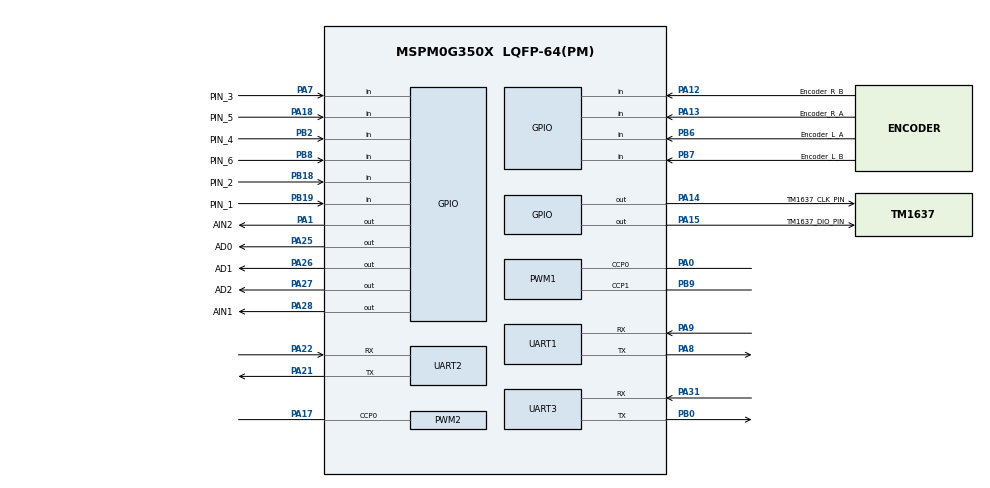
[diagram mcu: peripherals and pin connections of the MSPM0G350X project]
/**
 *
 * @cliArgs --device "MSPM0G350X" --part "Default" --package "LQFP-64(PM)" --product "mspm0_sdk@2.11.00.07"
 * @versions {"tool":"1.28.0+4712"}
 */

/**
 * Import the modules used in this configuration.
 */
const GPIO   = scripting.addModule("/ti/driverlib/GPIO", {}, false);
const GPIO1  = GPIO.addInstance();
const GPIO2  = GPIO.addInstance();
const GPIO3  = GPIO.addInstance();
const GPIO4  = GPIO.addInstance();
const GPIO5  = GPIO.addInstance();
const GPIO6  = GPIO.addInstance();
const GPIO7  = GPIO.addInstance();
const GPIO8  = GPIO.addInstance();
const GPIO9  = GPIO.addInstance();
const GPIO10 = GPIO.addInstance();
const GPIO11 = GPIO.addInstance();
const GPIO12 = GPIO.addInstance();
const GPIO13 = GPIO.addInstance();
const GPIO14 = GPIO.addInstance();
const PWM    = scripting.addModule("/ti/driverlib/PWM", {}, false);
const PWM1   = PWM.addInstance();
const PWM2   = PWM.addInstance();
const SYSCTL = scripting.addModule("/ti/driverlib/SYSCTL");
const TIMER  = scripting.addModule("/ti/driverlib/TIMER", {}, false);
const TIMER1 = TIMER.addInstance();
const UART   = scripting.addModule("/ti/driverlib/UART", {}, false);
const UART1  = UART.addInstance();
const UART2  = UART.addInstance();
const UART3  = UART.addInstance();

/**
 * Write custom configuration values to the imported modules.
 */
GPIO1.$name                          = "GPIO_MOTOR";
GPIO1.associatedPins.create(4);
GPIO1.associatedPins[0].$name        = "AIN1";
GPIO1.associatedPins[0].assignedPort = "PORTA";
GPIO1.associatedPins[0].assignedPin  = "28";
GPIO1.associatedPins[0].pin.$assign  = "PA28";
GPIO1.associatedPins[1].$name        = "AIN2";
GPIO1.associatedPins[1].assignedPort = "PORTA";
GPIO1.associatedPins[1].assignedPin  = "1";
GPIO1.associatedPins[1].pin.$assign  = "PA1";
GPIO1.associatedPins[2].assignedPort = "PORTA";
GPIO1.associatedPins[2].assignedPin  = "2";
GPIO1.associatedPins[2].$name        = "BIN1";
GPIO1.associatedPins[3].assignedPort = "PORTB";
GPIO1.associatedPins[3].assignedPin  = "24";
GPIO1.associatedPins[3].$name        = "BIN2";

const Board = scripting.addModule("/ti/driverlib/Board", {}, false);

GPIO2.$name                               = "GPIO_ENCODER_Encoder_L_A";
GPIO2.associatedPins[0].$name             = "Encoder_L_A";
GPIO2.associatedPins[0].direction         = "INPUT";
GPIO2.associatedPins[0].interruptEn       = true;
GPIO2.associatedPins[0].interruptPriority = "0";
GPIO2.associatedPins[0].polarity          = "RISE";
GPIO2.associatedPins[0].assignedPort      = "PORTB";
GPIO2.associatedPins[0].assignedPin       = "6";
GPIO2.associatedPins[0].internalResistor  = "PULL_UP";
GPIO2.associatedPins[0].pin.$assign       = "PB6";

GPIO3.$name                              = "GPIO_ENCODER_Encoder_L_B";
GPIO3.associatedPins[0].$name            = "Encoder_L_B";
GPIO3.associatedPins[0].direction        = "INPUT";
GPIO3.associatedPins[0].assignedPort     = "PORTB";
GPIO3.associatedPins[0].assignedPin      = "7";
GPIO3.associatedPins[0].internalResistor = "PULL_UP";
GPIO3.associatedPins[0].pin.$assign      = "PB7";

GPIO4.$name                               = "GPIO_ENCODER_Encoder_R_A";
GPIO4.associatedPins[0].$name             = "Encoder_R_A";
GPIO4.associatedPins[0].direction         = "INPUT";
GPIO4.associatedPins[0].interruptEn       = true;
GPIO4.associatedPins[0].interruptPriority = "0";
GPIO4.associatedPins[0].polarity          = "RISE";
GPIO4.associatedPins[0].assignedPort      = "PORTA";
GPIO4.associatedPins[0].assignedPin       = "13";
GPIO4.associatedPins[0].internalResistor  = "PULL_UP";
GPIO4.associatedPins[0].pin.$assign       = "PA13";

GPIO5.$name                              = "GPIO_ENCODER_Encoder_R_B";
GPIO5.associatedPins[0].$name            = "Encoder_R_B";
GPIO5.associatedPins[0].direction        = "INPUT";
GPIO5.associatedPins[0].assignedPort     = "PORTA";
GPIO5.associatedPins[0].assignedPin      = "12";
GPIO5.associatedPins[0].internalResistor = "PULL_UP";
GPIO5.associatedPins[0].pin.$assign      = "PA12";

GPIO6.$name                              = "GPIO_IR_GREY_PORT";
GPIO6.associatedPins.create(4);
GPIO6.associatedPins[0].assignedPort     = "PORTA";
GPIO6.associatedPins[0].internalResistor = "PULL_UP";
GPIO6.associatedPins[0].$name            = "AD0";
GPIO6.associatedPins[0].assignedPin      = "25";
GPIO6.associatedPins[0].pin.$assign      = "PA25";
GPIO6.associatedPins[1].assignedPort     = "PORTA";
GPIO6.associatedPins[1].assignedPin      = "26";
GPIO6.associatedPins[1].internalResistor = "PULL_UP";
GPIO6.associatedPins[1].$name            = "AD1";
GPIO6.associatedPins[1].pin.$assign      = "PA26";
GPIO6.associatedPins[2].assignedPort     = "PORTA";
GPIO6.associatedPins[2].internalResistor = "PULL_UP";
GPIO6.associatedPins[2].$name            = "AD2";
GPIO6.associatedPins[2].assignedPin      = "27";
GPIO6.associatedPins[2].pin.$assign      = "PA27";
GPIO6.associatedPins[3].assignedPort     = "PORTA";
GPIO6.associatedPins[3].assignedPin      = "24";
GPIO6.associatedPins[3].direction        = "INPUT";
GPIO6.associatedPins[3].internalResistor = "PULL_UP";
GPIO6.associatedPins[3].$name            = "OUT";

GPIO7.$name                          = "TM1637_CLK_PORT";
GPIO7.associatedPins[0].$name        = "TM1637_CLK_PIN";
GPIO7.associatedPins[0].assignedPort = "PORTA";
GPIO7.associatedPins[0].assignedPin  = "14";
GPIO7.associatedPins[0].pin.$assign  = "PA14";

GPIO8.$name                          = "TM1637_DIO_PORT";
GPIO8.associatedPins[0].$name        = "TM1637_DIO_PIN";
GPIO8.associatedPins[0].assignedPort = "PORTA";
GPIO8.associatedPins[0].assignedPin  = "15";
GPIO8.associatedPins[0].pin.$assign  = "PA15";

GPIO9.$name                              = "GPIO_KEY_1";
GPIO9.associatedPins[0].$name            = "PIN_1";
GPIO9.associatedPins[0].direction        = "INPUT";
GPIO9.associatedPins[0].internalResistor = "PULL_UP";
GPIO9.associatedPins[0].pin.$assign      = "PB19";

GPIO10.$name                              = "GPIO_KEY_2";
GPIO10.associatedPins[0].$name            = "PIN_2";
GPIO10.associatedPins[0].direction        = "INPUT";
GPIO10.associatedPins[0].internalResistor = "PULL_UP";
GPIO10.associatedPins[0].pin.$assign      = "PB18";

GPIO11.$name                              = "GPIO_KEY_3";
GPIO11.associatedPins[0].$name            = "PIN_3";
GPIO11.associatedPins[0].direction        = "INPUT";
GPIO11.associatedPins[0].internalResistor = "PULL_UP";
GPIO11.associatedPins[0].pin.$assign      = "PA7";

GPIO12.$name                              = "GPIO_KEY_4";
GPIO12.associatedPins[0].$name            = "PIN_4";
GPIO12.associatedPins[0].direction        = "INPUT";
GPIO12.associatedPins[0].internalResistor = "PULL_UP";
GPIO12.associatedPins[0].pin.$assign      = "PB2";

GPIO13.$name                              = "GPIO_KEY_5";
GPIO13.associatedPins[0].$name            = "PIN_5";
GPIO13.associatedPins[0].direction        = "INPUT";
GPIO13.associatedPins[0].internalResistor = "PULL_UP";
GPIO13.associatedPins[0].pin.$assign      = "PA18";

GPIO14.$name                              = "GPIO_KEY_6";
GPIO14.associatedPins[0].$name            = "PIN_6";
GPIO14.associatedPins[0].direction        = "INPUT";
GPIO14.associatedPins[0].internalResistor = "PULL_UP";
GPIO14.associatedPins[0].pin.$assign      = "PB8";

PWM1.$name                      = "PWM_0";
PWM1.timerStartTimer            = true;
PWM1.clockDivider               = 8;
PWM1.peripheral.$assign         = "TIMA0";
PWM1.peripheral.ccp0Pin.$assign = "PA0";
PWM1.peripheral.ccp1Pin.$assign = "PB9";
PWM1.PWM_CHANNEL_0.$name        = "ti_driverlib_pwm_PWMTimerCC0";
PWM1.PWM_CHANNEL_0.invert       = true;
PWM1.PWM_CHANNEL_1.$name        = "ti_driverlib_pwm_PWMTimerCC1";
PWM1.PWM_CHANNEL_1.invert       = true;
PWM1.ccp0PinConfig.$name        = "ti_driverlib_gpio_GPIOPinGeneric0";
PWM1.ccp1PinConfig.$name        = "ti_driverlib_gpio_GPIOPinGeneric1";

PWM2.$name                      = "PWM_1";
PWM2.clockDivider               = 8;
PWM2.ccIndex                    = [0];
PWM2.clockPrescale              = 4;
PWM2.timerCount                 = 20000;
PWM2.timerStartTimer            = true;
PWM2.pwmMode                    = "EDGE_ALIGN_UP";
PWM2.PWM_CHANNEL_0.$name        = "ti_driverlib_pwm_PWMTimerCC2";
PWM2.PWM_CHANNEL_0.ccValue      = 1500;
PWM2.ccp0PinConfig.$name        = "ti_driverlib_gpio_GPIOPinGeneric5";
PWM2.peripheral.$assign         = "TIMA1";
PWM2.peripheral.ccp0Pin.$assign = "PA17";

SYSCTL.forceDefaultClkConfig = true;

TIMER1.$name             = "TIMER_TICK";
TIMER1.timerClkDiv       = 8;
TIMER1.timerClkPrescale  = 10;
TIMER1.timerMode         = "PERIODIC";
TIMER1.timerPeriod       = "20 ms";
TIMER1.interrupts        = ["ZERO"];
TIMER1.interruptPriority = "3";

UART1.targetBaudRate                   = 115200;
UART1.$name                            = "UART_1";
UART1.enabledInterrupts                = ["OVERRUN_ERROR","RX"];
UART1.interruptPriority                = "0";
UART1.peripheral.$assign               = "UART1";
UART1.peripheral.rxPin.$assign         = "PA9";
UART1.peripheral.txPin.$assign         = "PA8";
UART1.txPinConfig.direction            = scripting.forceWrite("OUTPUT");
UART1.txPinConfig.hideOutputInversion  = scripting.forceWrite(false);
UART1.txPinConfig.onlyInternalResistor = scripting.forceWrite(false);
UART1.txPinConfig.passedPeripheralType = scripting.forceWrite("Digital");
UART1.txPinConfig.$name                = "ti_driverlib_gpio_GPIOPinGeneric2";
UART1.txPinConfig.enableConfig         = true;
UART1.rxPinConfig.hideOutputInversion  = scripting.forceWrite(false);
UART1.rxPinConfig.onlyInternalResistor = scripting.forceWrite(false);
UART1.rxPinConfig.passedPeripheralType = scripting.forceWrite("Digital");
UART1.rxPinConfig.$name                = "ti_driverlib_gpio_GPIOPinGeneric3";
UART1.rxPinConfig.enableConfig         = true;

UART2.targetBaudRate                   = 115200;
UART2.$name                            = "UART_2";
UART2.peripheral.$assign               = "UART2";
UART2.peripheral.rxPin.$assign         = "PA22";
UART2.peripheral.txPin.$assign         = "PA21";
UART2.txPinConfig.$name                = "ti_driverlib_gpio_GPIOPinGeneric6";
UART2.txPinConfig.direction            = scripting.forceWrite("OUTPUT");
UART2.txPinConfig.hideOutputInversion  = scripting.forceWrite(false);
UART2.txPinConfig.onlyInternalResistor = scripting.forceWrite(false);
UART2.txPinConfig.passedPeripheralType = scripting.forceWrite("Digital");
UART2.rxPinConfig.$name                = "ti_driverlib_gpio_GPIOPinGeneric7";
UART2.rxPinConfig.hideOutputInversion  = scripting.forceWrite(false);
UART2.rxPinConfig.onlyInternalResistor = scripting.forceWrite(false);
UART2.rxPinConfig.passedPeripheralType = scripting.forceWrite("Digital");

UART3.$name                    = "UART_0";
UART3.targetBaudRate           = 115200;
UART3.enabledInterrupts        = ["OVERRUN_ERROR","RX"];
UART3.interruptPriority        = "1";
UART3.peripheral.$assign       = "UART0";
UART3.peripheral.rxPin.$assign = "PA31";
UART3.peripheral.txPin.$assign = "PB0";
UART3.txPinConfig.$name        = "ti_driverlib_gpio_GPIOPinGeneric4";
UART3.rxPinConfig.$name        = "ti_driverlib_gpio_GPIOPinGeneric8";

/**
 * Pinmux solution for unlocked pins/peripherals. This ensures that minor changes to the automatic solver in a future
 * version of the tool will not impact the pinmux you originally saw.  These lines can be completely deleted in order to
 * re-solve from scratch.
 */
GPIO1.associatedPins[2].pin.$suggestSolution = "PA2";
GPIO1.associatedPins[3].pin.$suggestSolution = "PB24";
Board.peripheral.$suggestSolution            = "DEBUGSS";
Board.peripheral.swclkPin.$suggestSolution   = "PA20";
Board.peripheral.swdioPin.$suggestSolution   = "PA19";
GPIO6.associatedPins[3].pin.$suggestSolution = "PA24";
SYSCTL.peripheral.$suggestSolution           = "SYSCTL";
TIMER1.peripheral.$suggestSolution           = "TIMG0";
